# S32K324_M7 register map
Vendor: NXP Semiconductors; File version: 1.1
CPU: CM7 r0p1, little endian, MPU, FPU, VTOR, 4 interrupt priority bits
Registers are 32-bit, read-write, reset 0x0 unless marked. A register's access mark holds for its fields unless they carry their own. Offsets are from the block's base; [hi:lo] are bit positions; {n}, {i} and the like mark numbered series; 'fields as' and 'values as' point back to an identical list.

## SELFTEST_GPR
Base 0x403B0000
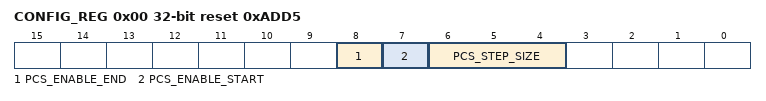
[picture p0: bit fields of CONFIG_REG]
0x00 CONFIG_REG reset 0xADD5 — Configuration register
  [8] PCS_ENABLE_END, [7] PCS_ENABLE_START, [6:4] PCS_STEP_SIZE
0x14 LBIST_PROG_REG reset 0x30050 — LBIST Program
  [7:0] LBIST_SHIFT_COUNT

## SEMA42
Base 0x40460000
0x00 GATE3 8-bit — Gate Register
  [3:0] GTFSM — Gate finite state machine
    0=UNLOCKED (The gate is unlocked (free).); {v}=LOCKED_BY_D{v-1} (Domain {v-1} locked the gate.) (v=1..15)
0x01 GATE2 8-bit — Gate Register
  fields as GATE3
0x02 GATE1 8-bit — Gate Register
  fields as GATE3
0x03 GATE0 8-bit — Gate Register
  fields as GATE3
0x04 GATE7 8-bit — Gate Register
  fields as GATE3
0x05 GATE6 8-bit — Gate Register
  fields as GATE3
0x06 GATE5 8-bit — Gate Register
  fields as GATE3
0x07 GATE4 8-bit — Gate Register
  fields as GATE3
0x08 GATE11 8-bit — Gate Register
  fields as GATE3
0x09 GATE10 8-bit — Gate Register
  fields as GATE3
0x0A GATE9 8-bit — Gate Register
  fields as GATE3
0x0B GATE8 8-bit — Gate Register
  fields as GATE3
0x0C GATE15 8-bit — Gate Register
  fields as GATE3
0x0D GATE14 8-bit — Gate Register
  fields as GATE3
0x0E GATE13 8-bit — Gate Register
  fields as GATE3
0x0F GATE12 8-bit — Gate Register
  fields as GATE3
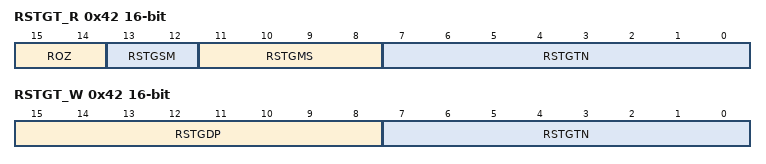
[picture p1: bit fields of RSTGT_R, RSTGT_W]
0x42 RSTGT_R 16-bit ro (RSTGT view) — Reset Gate Read
  [15:14] ROZ
  [13:12] RSTGSM — Reset gate finite state machine
    0=IDLE (Idle, waiting for the first data pattern write.); 1=WAITING (Waiting for the second data pattern write); 2=TWO_WRITE_DONE (The 2-write sequence has completed. Generate the specified gate reset(s). After the reset is performed, this machine returns to the idle (waiting for first data pattern write) state.)
  [11:8] RSTGMS — Reset gate domain
  [7:0] RSTGTN — Reset gate number
0x42 RSTGT_W 16-bit wo reset not defined (RSTGT view) — Reset Gate Write
  [15:8] RSTGDP — Reset gate data pattern
  [7:0] RSTGTN — Reset gate number

## QUADSPI_ARDB — ARDB
Base 0x68000000
{0x0+4i} ARDB[{i}] (i=0..127) ro — AHB RX Data Buffer Register
  [31:0] ARXD — ARDB provided RX buffer data

## MCM_0_CM7 — MCM
Base 0xE0080000
Same registers: MCM_1_CM7 0xE0080000 (alternate view of MCM_0_CM7)
0x00 PLREV 16-bit ro — SoC-defined Platform Revision
  [15:0] PLREV — The PLREV[15:0] field is specified by a platform input signal to define a software-visible revision number.
0x02 PCT 16-bit ro reset 0xAC70 — Processor Core Type
  [15:0] PCT — This MCM design supports the Arm Cortex M7 core. The following value identifies this core complex.
    0xAC70=Arm Cortex M7
0x0C CPCR reset 0x200 — Core Platform Control
  [27] CM7_AHBSPRI — AHB Slave Priority
    0=Uses a round-robin arbitration scheme; 1=AHB-slave access has priority over a core access
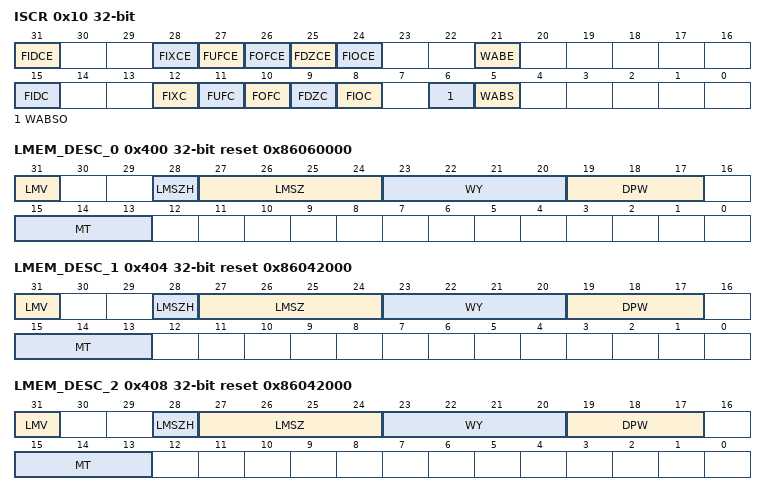
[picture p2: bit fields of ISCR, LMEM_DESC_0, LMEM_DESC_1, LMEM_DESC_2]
0x10 ISCR — Interrupt Status and Control
  [31] FIDCE — FPU Input Denormal Interrupt Enable
    0=Disable interrupt; 1=Enable interrupt
  [28] FIXCE — FPU Inexact Interrupt Enable
    0=Disable interrupt; 1=Enable interrupt
  [27] FUFCE — FPU Underflow Interrupt Enable
    0=Disable interrupt; 1=Enable interrupt
  [26] FOFCE — FPU Overflow Interrupt Enable
    0=Disable interrupt; 1=Enable interrupt
  [25] FDZCE — FPU Divide-by-Zero Interrupt Enable
    0=Disable interrupt; 1=Enable interrupt
  [24] FIOCE — FPU Invalid Operation Interrupt Enable
    0=Disable interrupt; 1=Enable interrupt
  [21] WABE — TCM Write Abort Interrupt Enable
    0=Disable interrupt; 1=Enable Interrupt
  [15] FIDC ro — FPU Input Denormal Interrupt Status
    0=No interrupt; 1=Interrupt occurred
  [12] FIXC ro — FPU Inexact Interrupt Status
    0=No interrupt; 1=Interrupt occurred
  [11] FUFC ro — FPU Underflow Interrupt Status
    0=No interrupt; 1=Interrupt occurred
  [10] FOFC ro — FPU Overflow Interrupt Status
    0=No interrupt; 1=Interrupt occurred
  [9] FDZC ro — FPU Divide-by-Zero Interrupt Status
    0=No interrupt; 1=Interrupt occurred
  [8] FIOC ro — FPU Invalid Operation Interrupt Status
    0=No interrupt; 1=Interrupt occurred
  [6] WABSO ro — Write Abort on Slave Overrun
    0=No write abort overrun; 1=Write abort overrun occurred
  [5] WABS write-1-clears — Write Abort on Slave
    0=No write abort occurred on AHBS interface; 1=Write abort occurred on AHBS interface
0x400 LMEM_DESC_0 reset 0x86060000 — Local Memory Descriptor 0
  [31] LMV ro — Local Memory Valid
    0=NOT_PRESENT (LMEMn not present); 1=PRESENT (LMEMn present)
  [28] LMSZH ro — LMEM Size Hole
    0=PWR_OF_2 (LMEMn is a power-of-2 capacity); 1=NOT_PWR_OF_2 (LMEMn is not a power-of-2, with capacity of 0.75 x LMSZ)
  [27:24] LMSZ ro — Local Memory Size
    0=0 KB; 1=1 KB; 2=2 KB; 3=4 KB; 4=8 KB; 5=16 KB; 6=32 KB; 7=64 KB; 8=128 KB; 9=256 KB; 10=512 KB; 11=1024 KB; 12=2048 KB; 13=4096 KB; 14=8192 KB; 15=16384 KB
  [23:20] WY ro — Level 1 Cache Ways
    0=No cache; 2=2-way set associative; 4=4-way set associative
  [19:17] DPW ro — Data Path Width
    2=WIDE_32 (LMEMn is 32-bits wide); 3=WIDE_64 (LMEMn is 64-bits wide)
  [15:13] MT ro — Memory Type
    0=ITCM; 1=DTCM; 2=ICACHE; 3=DCACHE
0x404 LMEM_DESC_1 reset 0x86042000 — Local Memory Descriptor 1
  fields as LMEM_DESC_0
0x408 LMEM_DESC_2 reset 0x86042000 — Local Memory Descriptor 2
  fields as LMEM_DESC_0
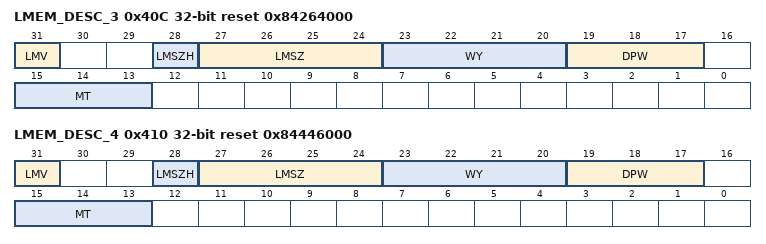
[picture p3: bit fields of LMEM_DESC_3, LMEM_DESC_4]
0x40C LMEM_DESC_3 reset 0x84264000 — Local Memory Descriptor 3
  fields as LMEM_DESC_0
0x410 LMEM_DESC_4 reset 0x84446000 — Local Memory Descriptor 4
  fields as LMEM_DESC_0
